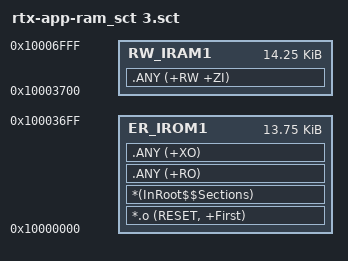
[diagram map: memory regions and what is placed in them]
; *************************************************************
; *** Scatter-Loading Description File generated by uVision ***
; *************************************************************

LR_IROM1 0x10000000 0x00003700  {    ; load region size_region
  ER_IROM1 0x10000000 0x00003700  {  ; load address = execution address
   *.o (RESET, +First)
   *(InRoot$$Sections)
   .ANY (+RO)
   .ANY (+XO)
  }
  RW_IRAM1 0x10003700 0x00003900  {  ; RW data
   .ANY (+RW +ZI)
  }
}

